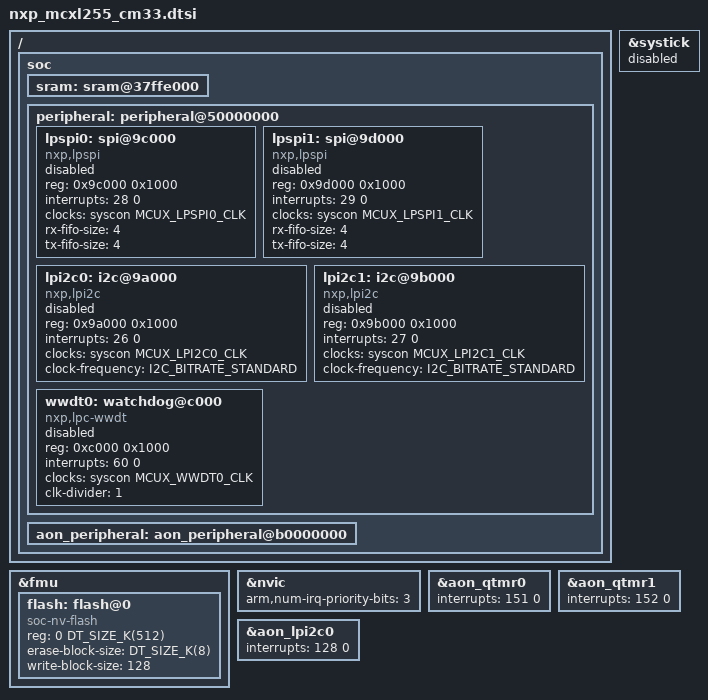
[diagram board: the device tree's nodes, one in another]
/*
 * Copyright 2025 NXP
 *
 * SPDX-License-Identifier: Apache-2.0
 */

#include <mem.h>
#include <zephyr/dt-bindings/i2c/i2c.h>

/ {
	soc {
		sram: sram@37ffe000 {
			ranges = <0x27ffe000 0x37ffe000 0x20000>,
				 <0xa1000000 0xb1000000 0x8000>;
		};

		peripheral: peripheral@50000000 {
			ranges = <0x0 0x50000000 0x10000000>;
		};

		aon_peripheral: aon_peripheral@b0000000 {
			ranges = <0x0 0xb0000000 0x10000000>;
		};
	};
};

#include "nxp_mcxl.dtsi"
#include "nxp_mcxl_aon.dtsi"

&peripheral {
	lpspi0: spi@9c000 {
		compatible = "nxp,lpspi";
		reg = <0x9c000 0x1000>;
		interrupts = <28 0>;
		clocks = <&syscon MCUX_LPSPI0_CLK>;
		#address-cells = <1>;
		#size-cells = <0>;
		status = "disabled";
		rx-fifo-size = <4>;
		tx-fifo-size = <4>;
	};

	lpspi1: spi@9d000 {
		compatible = "nxp,lpspi";
		reg = <0x9d000 0x1000>;
		interrupts = <29 0>;
		clocks = <&syscon MCUX_LPSPI1_CLK>;
		#address-cells = <1>;
		#size-cells = <0>;
		status = "disabled";
		rx-fifo-size = <4>;
		tx-fifo-size = <4>;
	};

	lpi2c0: i2c@9a000 {
		compatible = "nxp,lpi2c";
		reg = <0x9a000 0x1000>;
		interrupts = <26 0>;
		clocks = <&syscon MCUX_LPI2C0_CLK>;
		clock-frequency = <I2C_BITRATE_STANDARD>;
		#address-cells = <1>;
		#size-cells = <0>;
		status = "disabled";
	};

	lpi2c1: i2c@9b000 {
		compatible = "nxp,lpi2c";
		reg = <0x9b000 0x1000>;
		interrupts = <27 0>;
		clocks = <&syscon MCUX_LPI2C1_CLK>;
		clock-frequency = <I2C_BITRATE_STANDARD>;
		#address-cells = <1>;
		#size-cells = <0>;
		status = "disabled";
	};
};

&fmu {
	flash: flash@0 {
		compatible = "soc-nv-flash";
		reg = <0 DT_SIZE_K(512)>;
		erase-block-size = <DT_SIZE_K(8)>;
		write-block-size = <128>;
	};
};

&systick {
	status = "disabled";
};

&nvic {
	arm,num-irq-priority-bits = <3>;
};

&peripheral {
	wwdt0: watchdog@c000 {
		compatible = "nxp,lpc-wwdt";
		reg = <0xc000 0x1000>;
		interrupts = <60 0>;
		clocks = <&syscon MCUX_WWDT0_CLK>;
		status = "disabled";
		clk-divider = <1>;
	};
};

&aon_qtmr0 {
	interrupts = <151 0>;
};

&aon_qtmr1 {
	interrupts = <152 0>;
};

&aon_lpi2c0 {
	interrupts = <128 0>;
};
